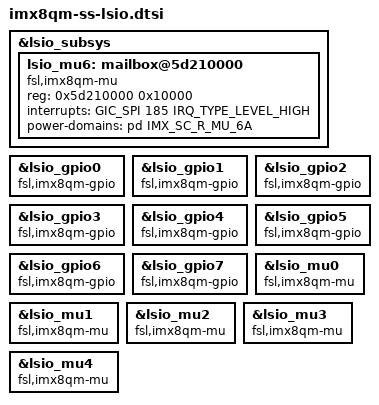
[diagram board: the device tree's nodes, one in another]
// SPDX-License-Identifier: GPL-2.0+
/*
 * Copyright 2019 NXP
 *	Dong Aisheng <aisheng.dong@nxp.com>
 */
&lsio_subsys {
	lsio_mu6: mailbox@5d210000 {
		compatible = "fsl,imx8qm-mu", "fsl,imx6sx-mu";
		reg = <0x5d210000 0x10000>;
		interrupts = <GIC_SPI 185 IRQ_TYPE_LEVEL_HIGH>;
		#mbox-cells = <2>;
		power-domains = <&pd IMX_SC_R_MU_6A>;
	};
};

&lsio_gpio0 {
	compatible = "fsl,imx8qm-gpio", "fsl,imx35-gpio";
};

&lsio_gpio1 {
	compatible = "fsl,imx8qm-gpio", "fsl,imx35-gpio";
};

&lsio_gpio2 {
	compatible = "fsl,imx8qm-gpio", "fsl,imx35-gpio";
};

&lsio_gpio3 {
	compatible = "fsl,imx8qm-gpio", "fsl,imx35-gpio";
};

&lsio_gpio4 {
	compatible = "fsl,imx8qm-gpio", "fsl,imx35-gpio";
};

&lsio_gpio5 {
	compatible = "fsl,imx8qm-gpio", "fsl,imx35-gpio";
};

&lsio_gpio6 {
	compatible = "fsl,imx8qm-gpio", "fsl,imx35-gpio";
};

&lsio_gpio7 {
	compatible = "fsl,imx8qm-gpio", "fsl,imx35-gpio";
};

&lsio_mu0 {
	compatible = "fsl,imx8qm-mu", "fsl,imx6sx-mu";
};

&lsio_mu1 {
	compatible = "fsl,imx8qm-mu", "fsl,imx6sx-mu";
};

&lsio_mu2 {
	compatible = "fsl,imx8qm-mu", "fsl,imx6sx-mu";
};

&lsio_mu3 {
	compatible = "fsl,imx8qm-mu", "fsl,imx6sx-mu";
};

&lsio_mu4 {
	compatible = "fsl,imx8qm-mu", "fsl,imx6sx-mu";
};
